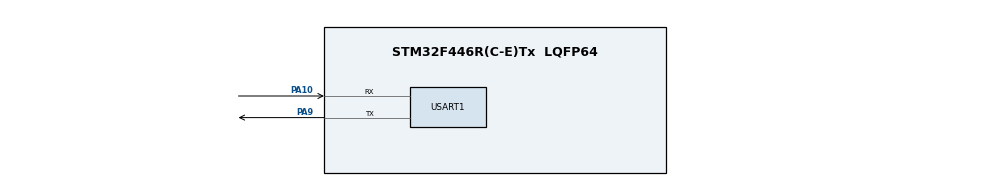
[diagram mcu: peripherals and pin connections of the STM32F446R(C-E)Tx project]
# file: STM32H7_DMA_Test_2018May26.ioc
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Dma.Request0=USART1_TX
Dma.USART1_TX.0.Direction=DMA_MEMORY_TO_PERIPH
Dma.USART1_TX.0.FIFOMode=DMA_FIFOMODE_DISABLE
Dma.USART1_TX.0.Instance=DMA2_Stream7
Dma.USART1_TX.0.MemDataAlignment=DMA_MDATAALIGN_BYTE
Dma.USART1_TX.0.MemInc=DMA_MINC_ENABLE
Dma.USART1_TX.0.Mode=DMA_NORMAL
Dma.USART1_TX.0.PeriphDataAlignment=DMA_PDATAALIGN_BYTE
Dma.USART1_TX.0.PeriphInc=DMA_PINC_DISABLE
Dma.USART1_TX.0.Priority=DMA_PRIORITY_LOW
FREERTOS.BinarySemaphores01=semTx,Static,semTxControlBlock
FREERTOS.MEMORY_ALLOCATION=2
FREERTOS.Tasks01=defaultTask,0,128,StartDefaultTask,Default,NULL,Dynamic,NULL,NULL;txTask,1,128,StartTxTask,Default,NULL,Dynamic,NULL,NULL
Mcu.Family=STM32F4
Mcu.Name=STM32F446R(C-E)Tx
Mcu.Package=LQFP64
NVIC.DMA2_Stream7_IRQn=true\:5\:0\:false\:false\:true\:true\:false
NVIC.PriorityGroup=NVIC_PRIORITYGROUP_4
NVIC.TIM1_UP_TIM10_IRQn=true\:0\:0\:false\:false\:true\:false\:false
NVIC.TimeBase=TIM1_UP_TIM10_IRQn
NVIC.TimeBaseIP=TIM1
NVIC.USART1_IRQn=true\:5\:0\:false\:false\:true\:true\:true
PA10.Mode=Asynchronous
PA10.Signal=USART1_RX
PA9.Mode=Asynchronous
PA9.Signal=USART1_TX
ProjectManager.HeapSize=0x200
ProjectManager.StackSize=0x400
ProjectManager.TargetToolchain=SW4STM32
RCC.CortexFreq_Value=16000000
RCC.USBFreq_Value=96000000
RCC.VCOOutputFreq_Value=192000000
USART1.VirtualMode=VM_ASYNC
VP_FREERTOS_VS_ENABLE.Mode=Enabled
VP_SYS_VS_tim1.Mode=TIM1
board=STM32H7_DMA_Test_2018May26

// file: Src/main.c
/**
  ******************************************************************************
  * @file           : main.c
  * @brief          : Main program body
  ******************************************************************************
  * This notice applies to any and all portions of this file
  * that are not between comment pairs USER CODE BEGIN and
  * USER CODE END. Other portions of this file, whether
  * inserted by the user or by software development tools
  * are owned by their respective copyright owners.
  *
  * Copyright (c) 2018 STMicroelectronics International N.V.
  * All rights reserved.
  *
  * Redistribution and use in source and binary forms, with or without
  * modification, are permitted, provided that the following conditions are met:
  *
  * 1. Redistribution of source code must retain the above copyright notice,
  *    this list of conditions and the following disclaimer.
  * 2. Redistributions in binary form must reproduce the above copyright notice,
  *    this list of conditions and the following disclaimer in the documentation
  *    and/or other materials provided with the distribution.
  * 3. Neither the name of STMicroelectronics nor the names of other
  *    contributors to this software may be used to endorse or promote products
  *    derived from this software without specific written permission.
  * 4. This software, including modifications and/or derivative works of this
  *    software, must execute solely and exclusively on microcontroller or
  *    microprocessor devices manufactured by or for STMicroelectronics.
  * 5. Redistribution and use of this software other than as permitted under
  *    this license is void and will automatically terminate your rights under
  *    this license.
  *
  * THIS SOFTWARE IS PROVIDED BY STMICROELECTRONICS AND CONTRIBUTORS "AS IS"
  * AND ANY EXPRESS, IMPLIED OR STATUTORY WARRANTIES, INCLUDING, BUT NOT
  * LIMITED TO, THE IMPLIED WARRANTIES OF MERCHANTABILITY, FITNESS FOR A
  * PARTICULAR PURPOSE AND NON-INFRINGEMENT OF THIRD PARTY INTELLECTUAL PROPERTY
  * RIGHTS ARE DISCLAIMED TO THE FULLEST EXTENT PERMITTED BY LAW. IN NO EVENT
  * SHALL STMICROELECTRONICS OR CONTRIBUTORS BE LIABLE FOR ANY DIRECT, INDIRECT,
  * INCIDENTAL, SPECIAL, EXEMPLARY, OR CONSEQUENTIAL DAMAGES (INCLUDING, BUT NOT
  * LIMITED TO, PROCUREMENT OF SUBSTITUTE GOODS OR SERVICES; LOSS OF USE, DATA,
  * OR PROFITS; OR BUSINESS INTERRUPTION) HOWEVER CAUSED AND ON ANY THEORY OF
  * LIABILITY, WHETHER IN CONTRACT, STRICT LIABILITY, OR TORT (INCLUDING
  * NEGLIGENCE OR OTHERWISE) ARISING IN ANY WAY OUT OF THE USE OF THIS SOFTWARE,
  * EVEN IF ADVISED OF THE POSSIBILITY OF SUCH DAMAGE.
  *
  ******************************************************************************
  */
#include "main.h"
#include "stm32f4xx_hal.h"
#include "cmsis_os.h"
#include "dma.h"
#include "usart.h"
#include "gpio.h"

/* USER CODE BEGIN PV */
/* Private variables ---------------------------------------------------------*/

/* USER CODE END PV */

void SystemClock_Config(void);
void MX_FREERTOS_Init(void);

/* USER CODE BEGIN PFP */
/* Private function prototypes -----------------------------------------------*/

/* USER CODE END PFP */

int main(void)
{

  /* MCU Configuration----------------------------------------------------------*/

  /* Reset of all peripherals, Initializes the Flash interface and the Systick. */
  HAL_Init();

  /* Configure the system clock */
  SystemClock_Config();

  /* Initialize all configured peripherals */
  MX_GPIO_Init();
  MX_DMA_Init();
  MX_USART1_UART_Init();

  /* Call init function for freertos objects (in freertos.c) */
  MX_FREERTOS_Init();

  /* Start scheduler */
  osKernelStart();

  /* We should never get here as control is now taken by the scheduler */

  /* Infinite loop */
  while (1)
  {

  }

}

void SystemClock_Config(void)
{

  RCC_OscInitTypeDef RCC_OscInitStruct;
  RCC_ClkInitTypeDef RCC_ClkInitStruct;

    /**Configure the main internal regulator output voltage
    */
  __HAL_RCC_PWR_CLK_ENABLE();

  __HAL_PWR_VOLTAGESCALING_CONFIG(PWR_REGULATOR_VOLTAGE_SCALE3);

    /**Initializes the CPU, AHB and APB busses clocks
    */
  RCC_OscInitStruct.OscillatorType = RCC_OSCILLATORTYPE_HSI;
  RCC_OscInitStruct.HSIState = RCC_HSI_ON;
  RCC_OscInitStruct.HSICalibrationValue = 16;
  RCC_OscInitStruct.PLL.PLLState = RCC_PLL_NONE;
  if (HAL_RCC_OscConfig(&RCC_OscInitStruct) != HAL_OK)
  {
    _Error_Handler(__FILE__, __LINE__);
  }

    /**Initializes the CPU, AHB and APB busses clocks
    */
  RCC_ClkInitStruct.ClockType = RCC_CLOCKTYPE_HCLK|RCC_CLOCKTYPE_SYSCLK
                              |RCC_CLOCKTYPE_PCLK1|RCC_CLOCKTYPE_PCLK2;
  RCC_ClkInitStruct.SYSCLKSource = RCC_SYSCLKSOURCE_HSI;
  RCC_ClkInitStruct.AHBCLKDivider = RCC_SYSCLK_DIV1;
  RCC_ClkInitStruct.APB1CLKDivider = RCC_HCLK_DIV1;
  RCC_ClkInitStruct.APB2CLKDivider = RCC_HCLK_DIV1;

  if (HAL_RCC_ClockConfig(&RCC_ClkInitStruct, FLASH_LATENCY_0) != HAL_OK)
  {
    _Error_Handler(__FILE__, __LINE__);
  }

    /**Configure the Systick interrupt time
    */
  HAL_SYSTICK_Config(HAL_RCC_GetHCLKFreq()/1000);

    /**Configure the Systick
    */
  HAL_SYSTICK_CLKSourceConfig(SYSTICK_CLKSOURCE_HCLK);

  /* SysTick_IRQn interrupt configuration */
  HAL_NVIC_SetPriority(SysTick_IRQn, 15, 0);
}

void HAL_TIM_PeriodElapsedCallback(TIM_HandleTypeDef *htim)
{
  if (htim->Instance == TIM1) {
    HAL_IncTick();
  }
}

void _Error_Handler(char *file, int line)
{
  while(1)
  {
  }
}

/************************ (C) COPYRIGHT STMicroelectronics *****END OF FILE****/

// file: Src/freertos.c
/**
  ******************************************************************************
  * File Name          : freertos.c
  * Description        : Code for freertos applications
  ******************************************************************************
  * This notice applies to any and all portions of this file
  * that are not between comment pairs USER CODE BEGIN and
  * USER CODE END. Other portions of this file, whether
  * inserted by the user or by software development tools
  * are owned by their respective copyright owners.
  *
  * Copyright (c) 2018 STMicroelectronics International N.V.
  * All rights reserved.
  *
  * Redistribution and use in source and binary forms, with or without
  * modification, are permitted, provided that the following conditions are met:
  *
  * 1. Redistribution of source code must retain the above copyright notice,
  *    this list of conditions and the following disclaimer.
  * 2. Redistributions in binary form must reproduce the above copyright notice,
  *    this list of conditions and the following disclaimer in the documentation
  *    and/or other materials provided with the distribution.
  * 3. Neither the name of STMicroelectronics nor the names of other
  *    contributors to this software may be used to endorse or promote products
  *    derived from this software without specific written permission.
  * 4. This software, including modifications and/or derivative works of this
  *    software, must execute solely and exclusively on microcontroller or
  *    microprocessor devices manufactured by or for STMicroelectronics.
  * 5. Redistribution and use of this software other than as permitted under
  *    this license is void and will automatically terminate your rights under
  *    this license.
  *
  * THIS SOFTWARE IS PROVIDED BY STMICROELECTRONICS AND CONTRIBUTORS "AS IS"
  * AND ANY EXPRESS, IMPLIED OR STATUTORY WARRANTIES, INCLUDING, BUT NOT
  * LIMITED TO, THE IMPLIED WARRANTIES OF MERCHANTABILITY, FITNESS FOR A
  * PARTICULAR PURPOSE AND NON-INFRINGEMENT OF THIRD PARTY INTELLECTUAL PROPERTY
  * RIGHTS ARE DISCLAIMED TO THE FULLEST EXTENT PERMITTED BY LAW. IN NO EVENT
  * SHALL STMICROELECTRONICS OR CONTRIBUTORS BE LIABLE FOR ANY DIRECT, INDIRECT,
  * INCIDENTAL, SPECIAL, EXEMPLARY, OR CONSEQUENTIAL DAMAGES (INCLUDING, BUT NOT
  * LIMITED TO, PROCUREMENT OF SUBSTITUTE GOODS OR SERVICES; LOSS OF USE, DATA,
  * OR PROFITS; OR BUSINESS INTERRUPTION) HOWEVER CAUSED AND ON ANY THEORY OF
  * LIABILITY, WHETHER IN CONTRACT, STRICT LIABILITY, OR TORT (INCLUDING
  * NEGLIGENCE OR OTHERWISE) ARISING IN ANY WAY OUT OF THE USE OF THIS SOFTWARE,
  * EVEN IF ADVISED OF THE POSSIBILITY OF SUCH DAMAGE.
  *
  ******************************************************************************
  */

#include "FreeRTOS.h"
#include "task.h"
#include "cmsis_os.h"

osThreadId defaultTaskHandle;
osThreadId txTaskHandle;
osSemaphoreId semTxHandle;
osStaticSemaphoreDef_t semTxControlBlock;

/* USER CODE BEGIN Variables */
#include "gpio.h"
#include "usart.h"
/* USER CODE END Variables */

void StartDefaultTask(void const * argument);
void StartTxTask(void const * argument);

void MX_FREERTOS_Init(void); /* (MISRA C 2004 rule 8.1) */

/* GetIdleTaskMemory prototype (linked to static allocation support) */
void vApplicationGetIdleTaskMemory( StaticTask_t **ppxIdleTaskTCBBuffer, StackType_t **ppxIdleTaskStackBuffer, uint32_t *pulIdleTaskStackSize );

/* Hook prototypes */

/* USER CODE BEGIN GET_IDLE_TASK_MEMORY */
static StaticTask_t xIdleTaskTCBBuffer;
static StackType_t xIdleStack[configMINIMAL_STACK_SIZE];

void vApplicationGetIdleTaskMemory( StaticTask_t **ppxIdleTaskTCBBuffer, StackType_t **ppxIdleTaskStackBuffer, uint32_t *pulIdleTaskStackSize )
{
  *ppxIdleTaskTCBBuffer = &xIdleTaskTCBBuffer;
  *ppxIdleTaskStackBuffer = &xIdleStack[0];
  *pulIdleTaskStackSize = configMINIMAL_STACK_SIZE;
  /* place for user code */
}
/* USER CODE END GET_IDLE_TASK_MEMORY */

/* Init FreeRTOS */

void MX_FREERTOS_Init(void) {

  /* Create the semaphores(s) */
  /* definition and creation of semTx */
  osSemaphoreStaticDef(semTx, &semTxControlBlock);
  semTxHandle = osSemaphoreCreate(osSemaphore(semTx), 1);

  /* Create the thread(s) */
  /* definition and creation of defaultTask */
  osThreadDef(defaultTask, StartDefaultTask, osPriorityNormal, 0, 128);
  defaultTaskHandle = osThreadCreate(osThread(defaultTask), NULL);

  /* definition and creation of txTask */
  osThreadDef(txTask, StartTxTask, osPriorityAboveNormal, 0, 128);
  txTaskHandle = osThreadCreate(osThread(txTask), NULL);

}

/* StartDefaultTask function */
void StartDefaultTask(void const * argument)
{

  for(;;)
  {
    osDelay(1);
  }
}

/* StartTxTask function */
void StartTxTask(void const * argument)
{
  /* USER CODE BEGIN StartTxTask */
  char myMessage[] = "Hello World";

  /* Infinite loop */
  for(;;)
  {
	    HAL_UART_Transmit_DMA(&huart1, (uint8_t*)myMessage, sizeof(myMessage));
	    xSemaphoreTake(semTxHandle, portMAX_DELAY);

	    vTaskDelay(100);
  }
  /* USER CODE END StartTxTask */
}

/* USER CODE BEGIN Application */
void HAL_UART_TxCpltCallback(UART_HandleTypeDef *huart)
{
	if(huart == &huart1){
		BaseType_t xHigherPriorityTaskWoken = pdTRUE;
		xSemaphoreGiveFromISR(semTxHandle, &xHigherPriorityTaskWoken);
	}
}
/* USER CODE END Application */

/************************ (C) COPYRIGHT STMicroelectronics *****END OF FILE****/
